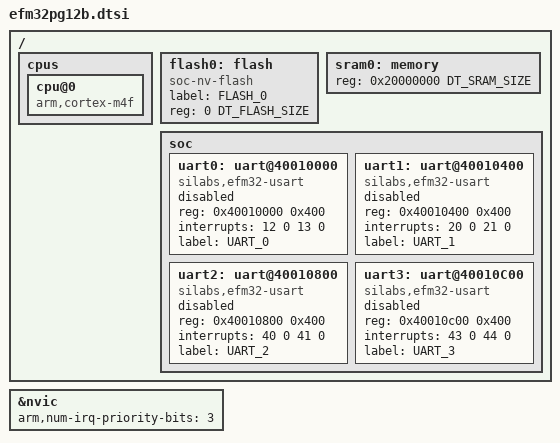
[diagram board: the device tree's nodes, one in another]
#include <arm/armv7-m.dtsi>
#include <silabs/mem.h>

/ {
	cpus {
		cpu@0 {
			compatible = "arm,cortex-m4f";
		};
	};

	flash0: flash {
		compatible = "soc-nv-flash";
		label = "FLASH_0";
		reg = <0 DT_FLASH_SIZE>;
	};

	sram0: memory {
		reg = <0x20000000 DT_SRAM_SIZE>;
	};

	soc {
		uart0: uart@40010000 { /* USART0 */
			compatible = "silabs,efm32-usart";
			reg = <0x40010000 0x400>;
			interrupts = <12 0 13 0>;
			status = "disabled";
			label = "UART_0";
		};

		uart1: uart@40010400 { /* USART1 */
			compatible = "silabs,efm32-usart";
			reg = <0x40010400 0x400>;
			interrupts = <20 0 21 0>;
			status = "disabled";
			label = "UART_1";
		};

		uart2: uart@40010800 { /* USART2 */
			compatible = "silabs,efm32-usart";
			reg = <0x40010800 0x400>;
			interrupts = <40 0 41 0>;
			status = "disabled";
			label = "UART_2";
		};

		uart3: uart@40010C00 { /* USART3 */
			compatible = "silabs,efm32-usart";
			reg = <0x40010c00 0x400>;
			interrupts = <43 0 44 0>;
			status = "disabled";
			label = "UART_3";
		};
	};
};

&nvic {
	arm,num-irq-priority-bits = <3>;
};
